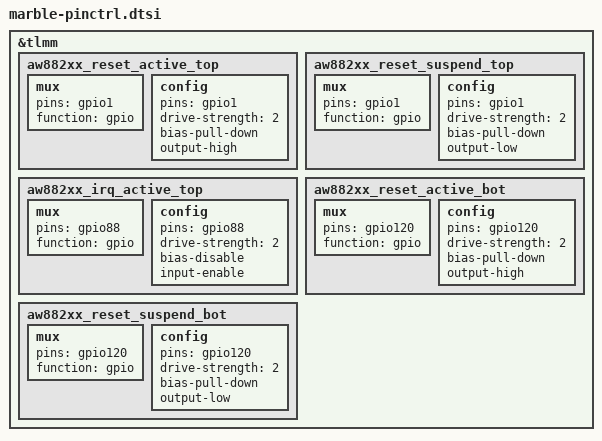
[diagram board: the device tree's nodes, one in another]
/*for marble pinctrl */
&tlmm {
    /* TOP Smart PA */
	aw882xx_reset_active_top:aw882xx_reset_active_top {
		/* active state */
		mux {
			pins = "gpio1";
			function = "gpio";
		};

		config {
			pins = "gpio1";
			drive-strength = <2>;
			bias-pull-down;
			output-high;
		};
	};

	aw882xx_reset_suspend_top:aw882xx_reset_suspend_top {
		/* sleep state */
		mux {
			pins = "gpio1";
			function = "gpio";
		};

		config {
			pins = "gpio1";
			drive-strength = <2>;
			bias-pull-down;
			output-low;
		};
	};

	/* TOP Smart PA INT*/
	aw882xx_irq_active_top:aw882xx_irq_active_top {
		mux {
			pins = "gpio88";
			function = "gpio";
		};

		config {
			pins = "gpio88";
			drive-strength = <2>;
			bias-disable;
			input-enable;
		};
	};

	/* BOT Smart PA */
	aw882xx_reset_active_bot:aw882xx_reset_active_bot {
		/* active state */
		mux {
			pins = "gpio120";
			function = "gpio";
		};

		config {
			pins = "gpio120";
			drive-strength = <2>;
			bias-pull-down;
			output-high;
		};
	};

	aw882xx_reset_suspend_bot:aw882xx_reset_suspend_bot {
		/* sleep state */
		mux {
			pins = "gpio120";
			function = "gpio";
		};

		config {
			pins = "gpio120";
			drive-strength = <2>;
			bias-pull-down;
			output-low;
		};
	};
};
